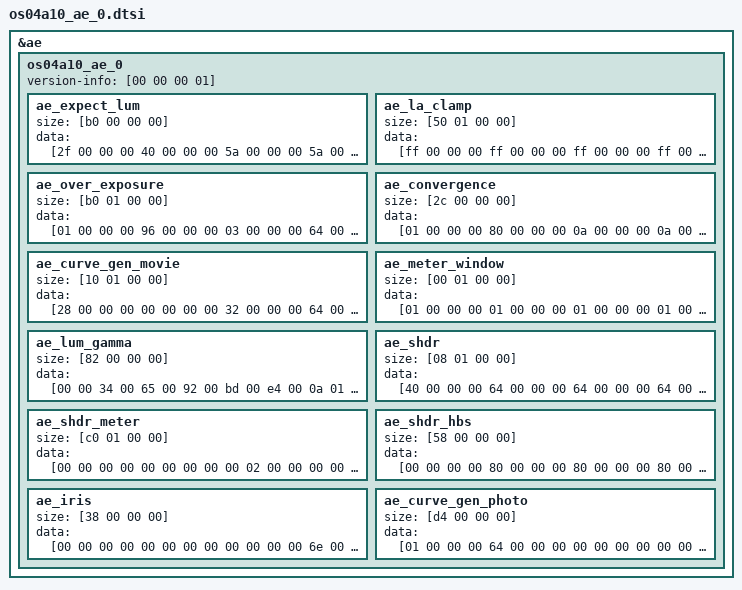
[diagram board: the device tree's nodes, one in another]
/*
 * Novatek Ltd. NVT98538 ISP part of dts
 */

&ae {
	os04a10_ae_0 {
		version-info = [00 00 00 01];
		ae_expect_lum {
			size = [b0 00 00 00];
			data = [2f 00 00 00 40 00 00 00 5a 00 00 00 5a 00 00 00 5f 00 00 00 64 00 00 00 64 00 00 00 64 00 00 00 64 00 00 00 64 00 00 00 64 00 00 00 64 00 00 00 64 00 00 00 64 00 00 00 64 00 00 00 64 00 00 00 64 00 00 00 64 00 00 00 64 00 00 00 64 00 00 00 64 00 00 00 64 00 00 00 64 00 00 00 64 00 00 00 64 00 00 00 64 00 00 00 64 00 00 00 64 00 00 00 64 00 00 00 64 00 00 00 64 00 00 00 64 00 00 00 64 00 00 00 64 00 00 00 64 00 00 00 64 00 00 00 64 00 00 00 64 00 00 00 64 00 00 00 64 00 00 00 64 00 00 00 64 00 00 00 64 00 00 00 64 00 00 00];
		};
		ae_la_clamp {
			size = [50 01 00 00];
			data = [ff 00 00 00 ff 00 00 00 ff 00 00 00 ff 00 00 00 ff 00 00 00 ff 00 00 00 ff 00 00 00 ff 00 00 00 ff 00 00 00 ff 00 00 00 ff 00 00 00 ff 00 00 00 ff 00 00 00 ff 00 00 00 ff 00 00 00 ff 00 00 00 ff 00 00 00 ff 00 00 00 ff 00 00 00 ff 00 00 00 ff 00 00 00 00 00 00 00 00 00 00 00 00 00 00 00 00 00 00 00 00 00 00 00 00 00 00 00 00 00 00 00 00 00 00 00 00 00 00 00 00 00 00 00 00 00 00 00 00 00 00 00 00 00 00 00 00 00 00 00 00 00 00 00 00 00 00 00 00 00 00 00 00 00 00 00 00 00 00 00 00 00 00 00 00 00 00 00 7d 00 00 00 7d 00 00 00 7d 00 00 00 7d 00 00 00 7d 00 00 00 7d 00 00 00 7d 00 00 00 7d 00 00 00 7d 00 00 00 7d 00 00 00 7d 00 00 00 7d 00 00 00 7d 00 00 00 7d 00 00 00 7d 00 00 00 7d 00 00 00 7d 00 00 00 7d 00 00 00 7d 00 00 00 7d 00 00 00 7d 00 00 00 00 00 00 00 00 00 00 00 00 00 00 00 00 00 00 00 00 00 00 00 00 00 00 00 00 00 00 00 00 00 00 00 00 00 00 00 00 00 00 00 00 00 00 00 00 00 00 00 00 00 00 00 00 00 00 00 00 00 00 00 00 00 00 00 00 00 00 00 00 00 00 00 00 00 00 00 00 00 00 00 00 00 00 00];
		};
		ae_over_exposure {
			size = [b0 01 00 00];
			data = [01 00 00 00 96 00 00 00 03 00 00 00 64 00 00 00 64 00 00 00 64 00 00 00 64 00 00 00 64 00 00 00 64 00 00 00 64 00 00 00 64 00 00 00 64 00 00 00 64 00 00 00 64 00 00 00 64 00 00 00 64 00 00 00 64 00 00 00 64 00 00 00 64 00 00 00 64 00 00 00 64 00 00 00 64 00 00 00 64 00 00 00 64 00 00 00 02 00 00 00 02 00 00 00 03 00 00 00 03 00 00 00 03 00 00 00 03 00 00 00 04 00 00 00 05 00 00 00 06 00 00 00 07 00 00 00 08 00 00 00 09 00 00 00 0a 00 00 00 0a 00 00 00 0a 00 00 00 0a 00 00 00 0a 00 00 00 0a 00 00 00 0a 00 00 00 0a 00 00 00 0a 00 00 00 02 00 00 00 02 00 00 00 03 00 00 00 03 00 00 00 03 00 00 00 03 00 00 00 04 00 00 00 05 00 00 00 06 00 00 00 07 00 00 00 08 00 00 00 09 00 00 00 0a 00 00 00 0a 00 00 00 0a 00 00 00 0a 00 00 00 0a 00 00 00 0a 00 00 00 0a 00 00 00 0a 00 00 00 0a 00 00 00 0a 00 00 00 0a 00 00 00 0a 00 00 00 0a 00 00 00 0a 00 00 00 0a 00 00 00 0a 00 00 00 0a 00 00 00 0a 00 00 00 0c 00 00 00 0f 00 00 00 0f 00 00 00 0f 00 00 00 0f 00 00 00 0f 00 00 00 0f 00 00 00 0f 00 00 00 0f 00 00 00 0f 00 00 00 0f 00 00 00 0f 00 00 00 03 00 00 00 03 00 00 00 03 00 00 00 03 00 00 00 03 00 00 00 03 00 00 00 03 00 00 00 03 00 00 00 03 00 00 00 05 00 00 00 08 00 00 00 08 00 00 00 08 00 00 00 08 00 00 00 08 00 00 00 08 00 00 00 08 00 00 00 08 00 00 00 08 00 00 00 08 00 00 00 08 00 00 00];
		};
		ae_convergence {
			size = [2c 00 00 00];
			data = [01 00 00 00 80 00 00 00 0a 00 00 00 0a 00 00 00 00 00 00 00 0a 00 00 00 64 00 00 00 00 00 00 00 1e 00 00 00 02 00 00 00 00 00 00 00];
		};
		ae_curve_gen_movie {
			size = [10 01 00 00];
			data = [28 00 00 00 00 00 00 00 32 00 00 00 64 00 00 00 00 00 00 00 00 00 00 00 20 4e 00 00 c8 00 00 00 00 00 00 00 00 00 00 00 00 00 00 00 00 00 00 00 00 00 00 00 00 00 00 00 00 00 00 00 00 00 00 00 00 00 00 00 00 00 00 00 00 00 00 00 00 00 00 00 00 00 00 00 00 00 00 00 00 00 00 00 00 00 00 00 00 00 00 00 00 00 00 00 00 00 00 00 00 00 00 00 00 00 00 00 00 00 00 00 00 00 00 00 00 00 00 00 00 00 00 00 00 00 00 00 00 00 00 00 00 00 00 00 00 00 00 00 00 00 00 00 00 00 00 00 00 00 00 00 00 00 00 00 00 00 00 00 00 00 00 00 00 00 00 00 00 00 00 00 00 00 00 00 00 00 00 00 00 00 00 00 00 00 00 00 00 00 00 00 02 00 00 00 00 20 03 00 40 00 00 00 00 04 00 00 00 00 00 00 b8 0b 00 00 b8 0b 00 00 60 09 00 00 60 09 00 00 d0 07 00 00 d0 07 00 00 dc 05 00 00 dc 05 00 00 b0 04 00 00 b0 04 00 00 00 00 00 00 e8 03 00 00 00 00 00 00];
		};
		ae_meter_window {
			size = [00 01 00 00];
			data = [01 00 00 00 01 00 00 00 01 00 00 00 01 00 00 00 01 00 00 00 01 00 00 00 01 00 00 00 01 00 00 00 01 00 00 00 02 00 00 00 02 00 00 00 02 00 00 00 02 00 00 00 02 00 00 00 02 00 00 00 01 00 00 00 01 00 00 00 02 00 00 00 03 00 00 00 03 00 00 00 03 00 00 00 03 00 00 00 02 00 00 00 01 00 00 00 01 00 00 00 02 00 00 00 03 00 00 00 04 00 00 00 04 00 00 00 03 00 00 00 02 00 00 00 01 00 00 00 01 00 00 00 02 00 00 00 03 00 00 00 04 00 00 00 04 00 00 00 03 00 00 00 02 00 00 00 01 00 00 00 01 00 00 00 02 00 00 00 03 00 00 00 03 00 00 00 03 00 00 00 03 00 00 00 02 00 00 00 01 00 00 00 01 00 00 00 02 00 00 00 02 00 00 00 02 00 00 00 02 00 00 00 02 00 00 00 02 00 00 00 01 00 00 00 01 00 00 00 01 00 00 00 01 00 00 00 01 00 00 00 01 00 00 00 01 00 00 00 01 00 00 00 01 00 00 00];
		};
		ae_lum_gamma {
			size = [82 00 00 00];
			data = [00 00 34 00 65 00 92 00 bd 00 e4 00 0a 01 2d 01 4e 01 6d 01 8b 01 a7 01 c1 01 da 01 f2 01 09 02 1f 02 34 02 48 02 5b 02 6d 02 7e 02 8f 02 9f 02 af 02 bd 02 cc 02 d9 02 e7 02 f3 02 00 03 0c 03 17 03 22 03 2d 03 37 03 41 03 4b 03 55 03 5e 03 67 03 6f 03 78 03 80 03 88 03 8f 03 97 03 9e 03 a5 03 ac 03 b3 03 b9 03 c0 03 c6 03 cc 03 d2 03 d7 03 dd 03 e3 03 e8 03 ed 03 f2 03 f7 03 fc 03 ff 03];
		};
		ae_shdr {
			size = [08 01 00 00];
			data = [40 00 00 00 64 00 00 00 64 00 00 00 64 00 00 00 64 00 00 00 64 00 00 00 64 00 00 00 64 00 00 00 64 00 00 00 64 00 00 00 64 00 00 00 64 00 00 00 64 00 00 00 64 00 00 00 64 00 00 00 64 00 00 00 64 00 00 00 64 00 00 00 64 00 00 00 64 00 00 00 64 00 00 00 64 00 00 00 00 01 00 00 00 01 00 00 00 01 00 00 00 01 00 00 00 01 00 00 00 01 00 00 00 01 00 00 00 01 00 00 00 01 00 00 00 01 00 00 00 01 00 00 00 01 00 00 00 01 00 00 00 01 00 00 00 01 00 00 00 01 00 00 00 01 00 00 00 01 00 00 00 01 00 00 00 01 00 00 00 01 00 00 64 00 00 00 64 00 00 00 64 00 00 00 64 00 00 00 64 00 00 00 64 00 00 00 64 00 00 00 64 00 00 00 64 00 00 00 64 00 00 00 64 00 00 00 64 00 00 00 64 00 00 00 64 00 00 00 64 00 00 00 64 00 00 00 64 00 00 00 64 00 00 00 64 00 00 00 64 00 00 00 64 00 00 00 00 00 00 00 00 00 00 00];
		};
		ae_shdr_meter {
			size = [c0 01 00 00];
			data = [00 00 00 00 00 00 00 00 00 02 00 00 00 00 00 00 86 03 00 00 89 04 00 00 41 05 00 00 d6 05 00 00 54 06 00 00 c3 06 00 00 27 07 00 00 82 07 00 00 d6 07 00 00 24 08 00 00 6e 08 00 00 b3 08 00 00 f5 08 00 00 34 09 00 00 70 09 00 00 a9 09 00 00 e0 09 00 00 15 0a 00 00 49 0a 00 00 7a 0a 00 00 aa 0a 00 00 d9 0a 00 00 06 0b 00 00 32 0b 00 00 5d 0b 00 00 87 0b 00 00 af 0b 00 00 d7 0b 00 00 fe 0b 00 00 24 0c 00 00 4a 0c 00 00 6e 0c 00 00 92 0c 00 00 b5 0c 00 00 d8 0c 00 00 f9 0c 00 00 1b 0d 00 00 3b 0d 00 00 5c 0d 00 00 7b 0d 00 00 9a 0d 00 00 b9 0d 00 00 d7 0d 00 00 f5 0d 00 00 12 0e 00 00 2f 0e 00 00 4c 0e 00 00 68 0e 00 00 84 0e 00 00 9f 0e 00 00 ba 0e 00 00 d5 0e 00 00 ef 0e 00 00 09 0f 00 00 23 0f 00 00 3c 0f 00 00 56 0f 00 00 6e 0f 00 00 87 0f 00 00 a0 0f 00 00 b8 0f 00 00 d0 0f 00 00 e7 0f 00 00 ff 0f 00 00 64 00 00 00 64 00 00 00 64 00 00 00 64 00 00 00 64 00 00 00 64 00 00 00 64 00 00 00 64 00 00 00 64 00 00 00 64 00 00 00 64 00 00 00 64 00 00 00 64 00 00 00 64 00 00 00 64 00 00 00 64 00 00 00 64 00 00 00 64 00 00 00 64 00 00 00 64 00 00 00 64 00 00 00 64 00 00 00 64 00 00 00 64 00 00 00 64 00 00 00 64 00 00 00 64 00 00 00 64 00 00 00 64 00 00 00 64 00 00 00 64 00 00 00 64 00 00 00 64 00 00 00 64 00 00 00 64 00 00 00 64 00 00 00 64 00 00 00 64 00 00 00 64 00 00 00 64 00 00 00 64 00 00 00 64 00 00 00 00 00 00 00 00 00 00 00];
		};
		ae_shdr_hbs {
			size = [58 00 00 00];
			data = [00 00 00 00 80 00 00 00 80 00 00 00 80 00 00 00 80 00 00 00 80 00 00 00 80 00 00 00 80 00 00 00 80 00 00 00 80 00 00 00 80 00 00 00 80 00 00 00 80 00 00 00 80 00 00 00 80 00 00 00 80 00 00 00 80 00 00 00 80 00 00 00 80 00 00 00 80 00 00 00 80 00 00 00 80 00 00 00];
		};
		ae_iris {
			size = [38 00 00 00];
			data = [00 00 00 00 00 00 00 00 00 00 00 00 6e 00 00 00 00 00 00 00 03 00 00 00 01 00 00 00 01 00 00 00 ff ff ff ff c8 00 00 00 f4 01 00 00 e8 03 00 00 00 00 00 00 00 00 00 00];
		};
		ae_curve_gen_photo {
			size = [d4 00 00 00];
			data = [01 00 00 00 64 00 00 00 00 00 00 00 00 00 00 00 35 82 00 00 20 03 00 00 00 00 00 00 00 00 00 00 6a 04 01 00 40 06 00 00 00 00 00 00 00 00 00 00 a0 86 01 00 80 0c 00 00 00 00 00 00 00 00 00 00 00 00 00 00 00 00 00 00 00 00 00 00 00 00 00 00 00 00 00 00 00 00 00 00 00 00 00 00 00 00 00 00 00 00 00 00 00 00 00 00 00 00 00 00 00 00 00 00 00 00 00 00 00 00 00 00 00 00 00 00 00 00 00 00 00 00 00 00 00 00 00 00 00 00 00 00 00 00 00 00 00 00 00 00 00 00 00 00 00 00 00 00 00 00 00 00 00 00 00 00 00 00 00 00 00 00 00 00 00 00 00 00 00 00 00 00 00 00 00 00 00 00 00 00 00 00 00 00 04 00 00 00 6a 04 01 00 00 19 00 00 01 00 00 00 e8 03 00 00];
		};
	};
};
